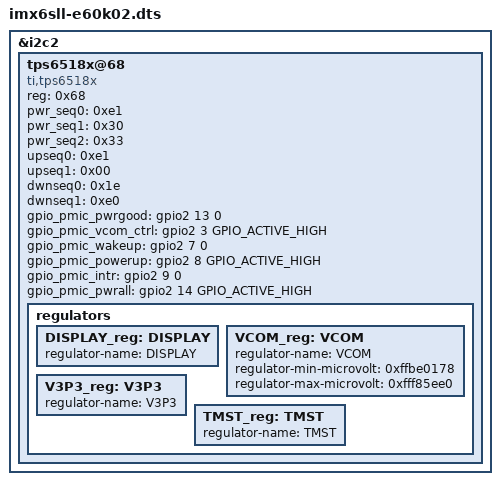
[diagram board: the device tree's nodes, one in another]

#include "imx6sll-e60k02-base.dts"

&i2c2 {
	tps6518x@68 {
		compatible = "ti,tps6518x";
		reg = <0x68>;
		/*
		 * power sequencing for TPS65180/65181
		 */
		pwr_seq0 = <0xe1>; /* [Vddh-seq=3 | Vpos-seq=2 | Vee-seq=0 | Vneg-seq=1] */
		pwr_seq1 = <0x30>; /* [Vneg-dly1=3 |Vee-dly0=0]  mSec */
		pwr_seq2 = <0x33>; /* [Vddh-dly3=3 | Vpos-dly2=3] mSec */
		/*
		 * power sequencing for TPS65185/65186
		 */
		upseq0 = <0xe1>;
		upseq1 = <0x00>;
		dwnseq0 = <0x1e>;
		dwnseq1 = <0xe0>;

		gpio_pmic_pwrgood = <&gpio2 13 0>;
		gpio_pmic_vcom_ctrl = <&gpio2 3 GPIO_ACTIVE_HIGH>;
		gpio_pmic_wakeup = <&gpio2 7 0>;
		gpio_pmic_powerup = <&gpio2 8 GPIO_ACTIVE_HIGH>;
		gpio_pmic_intr = <&gpio2 9 0>;

		/* gpio_pmic_v3p3 = <&gpio2 14 GPIO_ACTIVE_HIGH>; */
		gpio_pmic_pwrall = <&gpio2 14 GPIO_ACTIVE_HIGH>;

		regulators {
			DISPLAY_reg: DISPLAY {
				regulator-name = "DISPLAY";
			};

			VCOM_reg: VCOM {
				regulator-name = "VCOM";
				/* 2's-compliment, -4325000 */
				regulator-min-microvolt = <0xffbe0178>;
				/* 2's-compliment, -500000 */
				regulator-max-microvolt = <0xfff85ee0>;
			};

			V3P3_reg: V3P3 {
				regulator-name = "V3P3";
			};

			TMST_reg: TMST {
				regulator-name = "TMST";
			};

		};
	};
};


